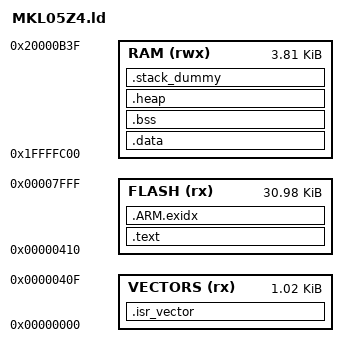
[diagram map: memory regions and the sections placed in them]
/*
 * KL05Z ARM GCC linker script file, Martin Kojtal (0xc0170)
 */

MEMORY
{
  VECTORS (rx) : ORIGIN = 0x00000000, LENGTH = 0x00000410
  FLASH (rx) : ORIGIN = 0x00000410, LENGTH = 32K - 0x00000410
  RAM (rwx) : ORIGIN = 0x1FFFFC00, LENGTH = 4K - 0xC0
}

/* Linker script to place sections and symbol values. Should be used together
 * with other linker script that defines memory regions FLASH and RAM.
 * It references following symbols, which must be defined in code:
 * _reset_init : Entry of reset handler
 *
 * It defines following symbols, which code can use without definition:
 * __exidx_start
 * __exidx_end
 * __etext
 * __data_start__
 * __preinit_array_start
 * __preinit_array_end
 * __init_array_start
 * __init_array_end
 * __fini_array_start
 * __fini_array_end
 * __data_end__
 * __bss_start__
 * __bss_end__
 * __end__
 * end
 * __HeapLimit
 * __StackLimit
 * __StackTop
 * __stack
 */
ENTRY(Reset_Handler)

SECTIONS
{
    .isr_vector :
    {
        __vector_table = .;
        KEEP(*(.vector_table))
        KEEP(*(.vectors .vectors.*))
         . = ALIGN(4);
    } > VECTORS

    .text :
    {
        *(.text*)
        *(.rodata .rodata* .gnu.linkonce.r.*)
        *(.ARM.extab* .gnu.linkonce.armextab.*)

        . = ALIGN(4);
        /* preinit data */
        KEEP(*(.init))

         . = ALIGN(4);
        PROVIDE_HIDDEN (__preinit_array_start = .);
        KEEP(*(.preinit_array))
        PROVIDE_HIDDEN (__preinit_array_end = .);

        . = ALIGN(4);
        /* init data */
        PROVIDE_HIDDEN (__init_array_start = .);
        KEEP(*(SORT(.init_array.*)))
        KEEP(*(.init_array))
        PROVIDE_HIDDEN (__init_array_end = .);

        . = ALIGN(4);
        /* .ctors */
        KEEP (*crtbegin.o(.ctors))
        KEEP (*(EXCLUDE_FILE (*crtend.o) .ctors))
        KEEP (*(SORT(.ctors.*)))
        KEEP (*crtend.o(.ctors))

        . = ALIGN(4);
        /* finit data */
        KEEP(*(.fini))
        PROVIDE_HIDDEN (__fini_array_start = .);
        KEEP(*(SORT(.fini_array.*)))
        KEEP(*(.fini_array))
        PROVIDE_HIDDEN (__fini_array_end = .);

        /* .dtors */
        KEEP (*crtbegin.o(.dtors))
        KEEP (*(EXCLUDE_FILE (*crtend.o) .dtors))
        KEEP (*(SORT(.dtors.*)))
        KEEP (*crtend.o(.dtors))

        KEEP(*(.eh_frame*))

        PROVIDE(motate_pin_change_interrupts_start = .);
        KEEP (*(.motate.pin_change_interrupts))
        PROVIDE(motate_pin_change_interrupts_end = .);
    } > FLASH

    __exidx_start = .;
    .ARM.exidx :
    {
        *(.ARM.exidx* .gnu.linkonce.armexidx.*)
    } > FLASH
    __exidx_end = .;

    __etext = .;

    .data : AT (__etext)
    {
        __data_start__ = .;
        *(vtable)
        *(.data*)

        /* Place C++ constructors (etc) here to move them to RAM. */

        . = ALIGN(4);
        /* All data end */
        __data_end__ = .;

    } > RAM

    .bss (NOLOAD) :
    {
        . = ALIGN(4);
        __bss_start__ = .;
        *(.bss*)
        *(COMMON)
        . = ALIGN(4);
        __bss_end__ = .;
    } > RAM

    .heap  (NOLOAD) :
    {
        __end__ = .;
        end = __end__;
        *(.heap*)
        __HeapLimit = .;
    } > RAM

    /* .stack_dummy section doesn't contains any symbols. It is only
     * used for linker to calculate size of stack sections, and assign
     * values to stack symbols later */
    .stack_dummy (NOLOAD) :
    {
        *(.stack)
    } > RAM

    /* Set stack top to end of RAM, and stack limit move down by
     * size of stack_dummy section */
    __StackTop = ORIGIN(RAM) + LENGTH(RAM);
    __StackLimit = __StackTop - SIZEOF(.stack_dummy);
    PROVIDE(__stack = __StackTop);

    /* Check if data + heap + stack exceeds RAM limit */
    ASSERT(__StackLimit >= __HeapLimit, "region RAM overflowed with stack")
	
  .stab 0 (NOLOAD) : { *(.stab) }
  .stabstr 0 (NOLOAD) : { *(.stabstr) }
  /* DWARF debug sections.
   * Symbols in the DWARF debugging sections are relative to the beginning
   * of the section so we begin them at 0.  */
  /* DWARF 1 */
  .debug          0 : { *(.debug) }
  .line           0 : { *(.line) }
  /* GNU DWARF 1 extensions */
  .debug_srcinfo  0 : { *(.debug_srcinfo) }
  .debug_sfnames  0 : { *(.debug_sfnames) }
  /* DWARF 1.1 and DWARF 2 */
  .debug_aranges  0 : { *(.debug_aranges) }
  .debug_pubnames 0 : { *(.debug_pubnames) }
  /* DWARF 2 */
  .debug_info     0 : { *(.debug_info .gnu.linkonce.wi.*) }
  .debug_abbrev   0 : { *(.debug_abbrev) }
  .debug_line     0 : { *(.debug_line) }
  .debug_frame    0 : { *(.debug_frame) }
  .debug_str      0 : { *(.debug_str) }
  .debug_loc      0 : { *(.debug_loc) }
  .debug_macinfo  0 : { *(.debug_macinfo) }
  /* SGI/MIPS DWARF 2 extensions */
  .debug_weaknames 0 : { *(.debug_weaknames) }
  .debug_funcnames 0 : { *(.debug_funcnames) }
  .debug_typenames 0 : { *(.debug_typenames) }
  .debug_varnames  0 : { *(.debug_varnames) }

  .note.gnu.arm.ident 0 : { KEEP (*(.note.gnu.arm.ident)) }
  .ARM.attributes 0 : { KEEP (*(.ARM.attributes)) }
  /DISCARD/ : { *(.note.GNU-stack) }

}
